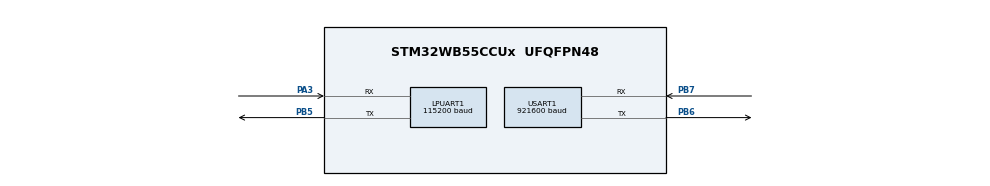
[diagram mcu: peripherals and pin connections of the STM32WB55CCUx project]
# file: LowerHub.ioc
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Dma.LPUART1_RX.0.Direction=DMA_PERIPH_TO_MEMORY
Dma.LPUART1_RX.0.EventEnable=DISABLE
Dma.LPUART1_RX.0.Instance=DMA1_Channel1
Dma.LPUART1_RX.0.MemDataAlignment=DMA_MDATAALIGN_BYTE
Dma.LPUART1_RX.0.MemInc=DMA_MINC_ENABLE
Dma.LPUART1_RX.0.Mode=DMA_NORMAL
Dma.LPUART1_RX.0.PeriphDataAlignment=DMA_PDATAALIGN_BYTE
Dma.LPUART1_RX.0.PeriphInc=DMA_PINC_DISABLE
Dma.LPUART1_RX.0.Polarity=HAL_DMAMUX_REQ_GEN_RISING
Dma.LPUART1_RX.0.Priority=DMA_PRIORITY_HIGH
Dma.LPUART1_RX.0.RequestNumber=1
Dma.LPUART1_RX.0.SignalID=NONE
Dma.LPUART1_RX.0.SyncEnable=DISABLE
Dma.LPUART1_RX.0.SyncPolarity=HAL_DMAMUX_SYNC_NO_EVENT
Dma.LPUART1_RX.0.SyncRequestNumber=1
Dma.LPUART1_RX.0.SyncSignalID=NONE
Dma.Request0=LPUART1_RX
Dma.Request1=USART1_RX
Dma.Request2=USART1_TX
Dma.USART1_RX.1.Direction=DMA_PERIPH_TO_MEMORY
Dma.USART1_RX.1.EventEnable=DISABLE
Dma.USART1_RX.1.Instance=DMA1_Channel2
Dma.USART1_RX.1.MemDataAlignment=DMA_MDATAALIGN_BYTE
Dma.USART1_RX.1.MemInc=DMA_MINC_ENABLE
Dma.USART1_RX.1.Mode=DMA_CIRCULAR
Dma.USART1_RX.1.PeriphDataAlignment=DMA_PDATAALIGN_BYTE
Dma.USART1_RX.1.PeriphInc=DMA_PINC_DISABLE
Dma.USART1_RX.1.Polarity=HAL_DMAMUX_REQ_GEN_RISING
Dma.USART1_RX.1.Priority=DMA_PRIORITY_HIGH
Dma.USART1_RX.1.RequestNumber=1
Dma.USART1_RX.1.SignalID=NONE
Dma.USART1_RX.1.SyncEnable=DISABLE
Dma.USART1_RX.1.SyncPolarity=HAL_DMAMUX_SYNC_NO_EVENT
Dma.USART1_RX.1.SyncRequestNumber=1
Dma.USART1_RX.1.SyncSignalID=NONE
Dma.USART1_TX.2.Direction=DMA_MEMORY_TO_PERIPH
Dma.USART1_TX.2.EventEnable=DISABLE
Dma.USART1_TX.2.Instance=DMA1_Channel3
Dma.USART1_TX.2.MemDataAlignment=DMA_MDATAALIGN_BYTE
Dma.USART1_TX.2.MemInc=DMA_MINC_ENABLE
Dma.USART1_TX.2.Mode=DMA_NORMAL
Dma.USART1_TX.2.PeriphDataAlignment=DMA_PDATAALIGN_BYTE
Dma.USART1_TX.2.PeriphInc=DMA_PINC_DISABLE
Dma.USART1_TX.2.Polarity=HAL_DMAMUX_REQ_GEN_RISING
Dma.USART1_TX.2.Priority=DMA_PRIORITY_HIGH
Dma.USART1_TX.2.RequestNumber=1
Dma.USART1_TX.2.SignalID=NONE
Dma.USART1_TX.2.SyncEnable=DISABLE
Dma.USART1_TX.2.SyncPolarity=HAL_DMAMUX_SYNC_NO_EVENT
Dma.USART1_TX.2.SyncRequestNumber=1
Dma.USART1_TX.2.SyncSignalID=NONE
LPUART1.BaudRate=115200
LPUART1.OverrunDisableParam=UART_ADVFEATURE_OVERRUN_DISABLE
Mcu.Family=STM32WB
Mcu.Name=STM32WB55CCUx
Mcu.Package=UFQFPN48
NVIC.DMA1_Channel1_IRQn=true\:0\:0\:false\:false\:true\:false\:true\:true
NVIC.DMA1_Channel2_IRQn=true\:0\:0\:false\:false\:true\:false\:true\:true
NVIC.DMA1_Channel3_IRQn=true\:0\:0\:false\:false\:true\:false\:true\:true
NVIC.HSEM_IRQn=true\:0\:0\:false\:false\:true\:false\:true\:true
NVIC.IPCC_C1_RX_IRQn=true\:0\:0\:false\:false\:true\:true\:true\:true
NVIC.IPCC_C1_TX_IRQn=true\:0\:0\:false\:false\:true\:true\:true\:true
NVIC.LPUART1_IRQn=true\:0\:0\:false\:false\:true\:true\:true\:true
NVIC.PriorityGroup=NVIC_PRIORITYGROUP_4
NVIC.USART1_IRQn=true\:0\:0\:false\:false\:true\:true\:true\:true
OSC_IN.Mode=HSE-External-Oscillator
OSC_IN.Signal=RCC_OSC_IN
OSC_OUT.Mode=HSE-External-Oscillator
OSC_OUT.Signal=RCC_OSC_OUT
PA13.Mode=Serial_Wire
PA13.Signal=SYS_JTMS-SWDIO
PA14.Mode=Serial_Wire
PA14.Signal=SYS_JTCK-SWCLK
PA3.Mode=Asynchronous
PA3.Signal=LPUART1_RX
PB3.GPIO_Label=SWO
PB3.Mode=Trace_Asynchronous_SW
PB3.Signal=SYS_JTDO-SWO
PB5.Mode=Asynchronous
PB5.Signal=LPUART1_TX
PB6.Mode=Asynchronous
PB6.Signal=USART1_TX
PB7.Mode=Asynchronous
PB7.Signal=USART1_RX
PC14-OSC32_IN.Mode=LSE-External-Oscillator
PC14-OSC32_IN.Signal=RCC_OSC32_IN
PC15-OSC32_OUT.Mode=LSE-External-Oscillator
PC15-OSC32_OUT.Signal=RCC_OSC32_OUT
ProjectManager.HeapSize=0x200
ProjectManager.StackSize=0x400
ProjectManager.TargetToolchain=STM32CubeIDE
RCC.ADCFreq_Value=48000000
RCC.AHBFreq_Value=32000000
RCC.APB1Freq_Value=32000000
RCC.APB1TimFreq_Value=32000000
RCC.APB2Freq_Value=32000000
RCC.APB2TimFreq_Value=32000000
RCC.APB3Freq_Value=16000000
RCC.CortexFreq_Value=32000000
RCC.HCLKFreq_Value=32000000
RCC.HSE_VALUE=32000000
RCC.HSI48_VALUE=48000000
RCC.HSI_VALUE=16000000
RCC.MSIClockRange=RCC_MSIRANGE_10
RCC.PLLM=RCC_PLLM_DIV2
RCC.PLLSAI1N=6
RCC.PLLSourceVirtual=RCC_PLLSOURCE_HSE
RCC.SYSCLKFreq_VALUE=32000000
RCC.USBFreq_Value=48000000
RCC.VCOOutputFreq_Value=128000000
RF1.Mode=RF1_Activate
RF1.Signal=RF_RF1
USART1.BaudRate=921600
USART1.VirtualMode-Asynchronous=VM_ASYNC
STM32_WPAN.AD_TYPE_COMPLETE_LOCAL_NAME=HUB0002
STM32_WPAN.AD_TYPE_COMPLETE_LOCAL_NAME_LENGTH=8
STM32_WPAN.CFG_BLE_DATA_LENGTH_EXTENSION=1
STM32_WPAN.CFG_BLE_MAX_ATT_MTU=247
STM32_WPAN.CFG_BLE_NUM_GATT_ATTRIBUTES=9
STM32_WPAN.CFG_BLE_NUM_GATT_SERVICES=2
STM32_WPAN.CFG_BLE_NUM_LINK=6
STM32_WPAN.CFG_GAP_DEVICE_NAME=HUB0002
STM32_WPAN.CFG_GAP_DEVICE_NAME_LENGTH=8
STM32_WPAN.CFG_IDENTITY_ADDRESS=GAP_STATIC_RANDOM_ADDR
STM32_WPAN.CFG_LP_CONN_ADV_INTERVAL_MAX=30
STM32_WPAN.CFG_LP_CONN_ADV_INTERVAL_MAX_HEXA=0x0030
STM32_WPAN.CFG_LP_CONN_ADV_INTERVAL_MIN=15
STM32_WPAN.CFG_LP_CONN_ADV_INTERVAL_MIN_HEXA=0x0018
STM32_WPAN.CFG_LSCLK_LSE=0
STM32_WPAN.CFG_TX_POWER=(0x1F) /* 6dBm */
STM32_WPAN.CUSTOM_P2P_SERVER=Disabled
STM32_WPAN.CUSTOM_TEMPLATE=Enabled
STM32_WPAN.GAP_CENTRAL_ROLE=4
STM32_WPAN.GAP_PERIPHERAL_ROLE=0
STM32_WPAN.INCLUDE_AD_TYPE_128_BIT_SERV_UUID_CMPLT_LIST=0
STM32_WPAN.INCLUDE_AD_TYPE_16_BIT_SERV_UUID_CMPLT_LIST=0
STM32_WPAN.INCLUDE_AD_TYPE_COMPLETE_LOCAL_NAME=0
STM32_WPAN.L2CAP_REQUEST_NEW_CONN_PARAM=1
STM32_WPAN.NUMBER_OF_SERVICES=0
VP_HSEM_VS_HSEM.Mode=HSEM_Activate
VP_IPCC_VS_IPCC.Mode=IPCC_Activate
VP_MEMORYMAP_VS_MEMORYMAP.Mode=CurAppReg
VP_RTC_VS_RTC_Activate.Mode=RTC_Enabled
VP_SEQUENCER_VS_SEQUENCER.Mode=SEQUENCER_Enabled
VP_STM32_WPAN_VS_BLE_HOST.Mode=STM32_WPAN_Enabled
VP_TINY_LPM_VS_TINY_LPM.Mode=TINY_LPM_Enabled
board=custom

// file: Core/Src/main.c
/* USER CODE BEGIN Header */
/**
  ******************************************************************************
  * @file           : main.c
  * @brief          : Main program body
  ******************************************************************************
  * @attention
  *
  * Copyright (c) 2026 STMicroelectronics.
  * All rights reserved.
  *
  * This software is licensed under terms that can be found in the LICENSE file
  * in the root directory of this software component.
  * If no LICENSE file comes with this software, it is provided AS-IS.
  *
  ******************************************************************************
  */
/* USER CODE END Header */
#include "main.h"
#include "dma.h"
#include "ipcc.h"
#include "usart.h"
#include "rf.h"
#include "rtc.h"
#include "gpio.h"
#include "iwdg.h"

/* USER CODE BEGIN Includes */

void exo_lower_hub_bridge_init(void);
void exo_lower_hub_bridge_process(void);
uint32_t exo_lower_hub_bridge_progress_counter(void);
void exo_hub_central_client_process(void);
uint32_t exo_hub_central_client_progress_counter(void);

/* USER CODE END Includes */

void SystemClock_Config(void);
void PeriphCommonClock_Config(void);

int main(void)
{

  /* MCU Configuration--------------------------------------------------------*/

  /* Reset of all peripherals, Initializes the Flash interface and the Systick. */
  HAL_Init();
  /* Config code for STM32_WPAN (HSE Tuning must be done before system clock configuration) */
  MX_APPE_Config();

  /* Configure the system clock */
  SystemClock_Config();

  /* Configure the peripherals common clocks */
  PeriphCommonClock_Config();

  /* IPCC initialisation */
  MX_IPCC_Init();

  /* Initialize all configured peripherals */
  MX_GPIO_Init();
  MX_DMA_Init();
  MX_RTC_Init();
  MX_LPUART1_UART_Init();
  MX_USART1_UART_Init();
  MX_RF_Init();
  /* USER CODE BEGIN 2 */

  exo_lower_hub_bridge_init();

  /* USER CODE END 2 */

  /* Init code for STM32_WPAN */
  MX_APPE_Init();
  /* Start the watchdog only after BLE, UART/DMA, and bridge startup has
   * completed. The loop below arms refresh only after both service paths run. */
  MX_IWDG_Init();

  /* Infinite loop */
  /* USER CODE BEGIN WHILE */
  while (1)
  {
    static uint32_t last_ble_progress = 0U;
    static uint32_t last_bridge_progress = 0U;
    static uint8_t watchdog_armed = 0U;
    /* USER CODE END WHILE */
    MX_APPE_Process();
    exo_hub_central_client_process();
    exo_lower_hub_bridge_process();
    {
      const uint32_t ble_progress = exo_hub_central_client_progress_counter();
      const uint32_t bridge_progress = exo_lower_hub_bridge_progress_counter();
      if (watchdog_armed == 0U && ble_progress != 0U && bridge_progress != 0U)
      {
        watchdog_armed = 1U;
      }
      if (watchdog_armed != 0U &&
          ble_progress != last_ble_progress &&
          bridge_progress != last_bridge_progress)
      {
        exo_lower_hub_iwdg_refresh();
      }
      last_ble_progress = ble_progress;
      last_bridge_progress = bridge_progress;
    }

  }
}

void SystemClock_Config(void)
{
  RCC_OscInitTypeDef RCC_OscInitStruct = {0};
  RCC_ClkInitTypeDef RCC_ClkInitStruct = {0};

  /** Configure the main internal regulator output voltage
  */
  __HAL_PWR_VOLTAGESCALING_CONFIG(PWR_REGULATOR_VOLTAGE_SCALE1);

  /** Initializes the RCC Oscillators according to the specified parameters
  * in the RCC_OscInitTypeDef structure.
  */
  RCC_OscInitStruct.OscillatorType = RCC_OSCILLATORTYPE_HSI|RCC_OSCILLATORTYPE_LSI1
                              |RCC_OSCILLATORTYPE_HSE|RCC_OSCILLATORTYPE_MSI;
  RCC_OscInitStruct.HSEState = RCC_HSE_ON;
  RCC_OscInitStruct.HSIState = RCC_HSI_ON;
  RCC_OscInitStruct.MSIState = RCC_MSI_ON;
  RCC_OscInitStruct.HSICalibrationValue = RCC_HSICALIBRATION_DEFAULT;
  RCC_OscInitStruct.MSICalibrationValue = RCC_MSICALIBRATION_DEFAULT;
  RCC_OscInitStruct.MSIClockRange = RCC_MSIRANGE_10;
  RCC_OscInitStruct.LSIState = RCC_LSI_ON;
  RCC_OscInitStruct.PLL.PLLState = RCC_PLL_NONE;
  if (HAL_RCC_OscConfig(&RCC_OscInitStruct) != HAL_OK)
  {
    Error_Handler();
  }

  /** Configure the SYSCLKSource, HCLK, PCLK1 and PCLK2 clocks dividers
  */
  RCC_ClkInitStruct.ClockType = RCC_CLOCKTYPE_HCLK4|RCC_CLOCKTYPE_HCLK2
                              |RCC_CLOCKTYPE_HCLK|RCC_CLOCKTYPE_SYSCLK
                              |RCC_CLOCKTYPE_PCLK1|RCC_CLOCKTYPE_PCLK2;
  RCC_ClkInitStruct.SYSCLKSource = RCC_SYSCLKSOURCE_MSI;
  RCC_ClkInitStruct.AHBCLKDivider = RCC_SYSCLK_DIV1;
  RCC_ClkInitStruct.APB1CLKDivider = RCC_HCLK_DIV1;
  RCC_ClkInitStruct.APB2CLKDivider = RCC_HCLK_DIV1;
  RCC_ClkInitStruct.AHBCLK2Divider = RCC_SYSCLK_DIV1;
  RCC_ClkInitStruct.AHBCLK4Divider = RCC_SYSCLK_DIV1;

  if (HAL_RCC_ClockConfig(&RCC_ClkInitStruct, FLASH_LATENCY_1) != HAL_OK)
  {
    Error_Handler();
  }
}

void PeriphCommonClock_Config(void)
{
  RCC_PeriphCLKInitTypeDef PeriphClkInitStruct = {0};

  /** Initializes the peripherals clock
  */
  PeriphClkInitStruct.PeriphClockSelection = RCC_PERIPHCLK_SMPS|RCC_PERIPHCLK_RFWAKEUP;
  PeriphClkInitStruct.RFWakeUpClockSelection = RCC_RFWKPCLKSOURCE_HSE_DIV1024;
  PeriphClkInitStruct.SmpsClockSelection = RCC_SMPSCLKSOURCE_HSI;
  PeriphClkInitStruct.SmpsDivSelection = RCC_SMPSCLKDIV_RANGE1;

  if (HAL_RCCEx_PeriphCLKConfig(&PeriphClkInitStruct) != HAL_OK)
  {
    Error_Handler();
  }
}

void Error_Handler(void)
{
  __disable_irq();
  while (1)
  {
  }
}
